# CAMERARX_CORE_0 register map
Vendor: Texas Instruments
Peripheral module from a debugger description file (folder am571x).
Registers are 32-bit, access not given, reset 0x427 unless marked. A register's access mark holds for its fields unless they carry their own. Offsets are as the file gives them; lines under a group give offsets from that group; [hi:lo] are bit positions; {n}, {i} and the like mark numbered series; 'fields as' and 'values as' point back to an identical list; <NAME> marks a mode.

## CAMERARX_CORE_0
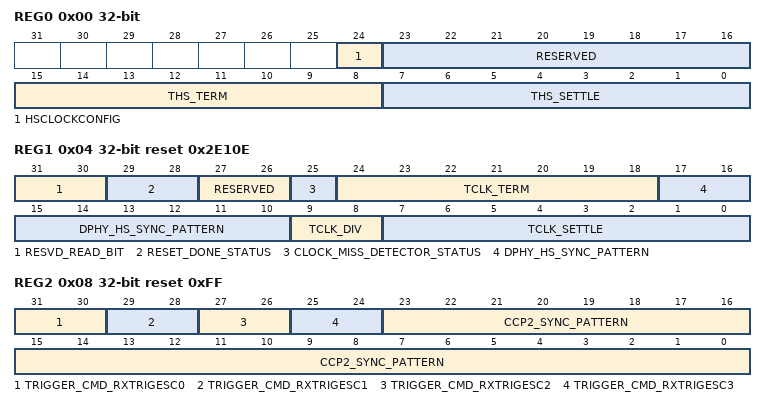
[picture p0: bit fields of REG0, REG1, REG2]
0x00 REG0 — First register. Note: For detailed description on parameter functionality, refer to MIPI D-PHY Specification v1.00.00.
  [24] HSCLOCKCONFIG rw — Disable clock missing detector
  [23:16] RESERVED ro — Read returns zero
  [15:8] THS_TERM rw — THS_TERM timing parameter in multiples of DDR clock frequency. Effective time for enabling of termination = synchronizer delay + timer delay + LPRX delay + combinational routing delay ~ (1–2)* DDRCLK + THS-TERM + ~ (1 –15) ns. Programmed value = floor(20 ns/DDR_CLK), where DDR_CLK is the period of the CSI-2 I/O lane rate. Default value: 4 (for 400 MHz).
  [7:0] THS_SETTLE rw — THS_SETTLE timing parameter in multiples of DDR clock frequency. Effective THS_SETTLE seen on line (starting to look for sync pattern) = synchronizer delay + timer delay + LPRX delay + combinational routing delay – pipeline delay in HS data path ~ (1–2)* DDRCLK + THS-SETTLE + ~ (1–15) ns –1*DDRCLK. Programmed value = floor(105 ns/DDR_CLK) + 4, where DDR_CLK is the period of the CSI-2 I/O lane rate. Default value: 39 (for 400 MHz). Minimum supported THS-SETTLE programmed value = 3.
0x04 REG1 reset 0x2E10E — Second register. Note: For detailed description on parameter functionality, refer to MIPI D-PHY Specification v1.00.00.
  [31:30] RESVD_READ_BIT — Reserved bit (access NA)
  [29:28] RESET_DONE_STATUS ro — Reset done read bits.
  [27:26] RESERVED rw — Write 0 for future compatibility.
  [25] CLOCK_MISS_DETECTOR_STATUS ro — Clock missing detector status. Internal debug bit. 1: Error in clock missing detector.
    0=CLKMISS_CAMSS_0 (Clock missing detector successful Note: CLKMISS detector is likely to malfunction, if tclk-trail section CAMSS Interrupt Events (60ns) is not honoured.)
  [24:18] TCLK_TERM rw — TCLK_TERM timing parameter in multiples of CTRLCLK Effective time for enabling of termination = synchronizer delay + timer delay + LPRX delay + combinational routing delay ~ (1–2)* CTRLCLK + TCLK_TERM + ~ (1–15) ns Programmed value = ceil(9.5 / CTRLCLK period) – 1 Default value : 0 (for 96 MHz)
  [17:10] DPHY_HS_SYNC_PATTERN rw — DPHY mode HS sync pattern in byte order (reverse of received order) See, CSI2 PHY Error Signals.
  [9:8] TCLK_DIV rw — CTRLCLK_DIV_FACTOR Divide factor for CTRLCLK for CLKMISS detector Programmed value = ceil (15ns/CTRLCLK Period) - 1 Default value: 1 (for 96 MHz) CLKMISS detection time = (5*TCLK_DIV+1)*(CTRLCLK period) &lt; 60ns Note: Only the CTRLCLK frequencies that satisfie above relationship are allowed. Typically, 96MHz will be used at CTRLCLK.
  [7:0] TCLK_SETTLE rw — TCLK_SETTLE timing parameter in multiples of CTRLCLK Clock Effective TCLK_SETTLE = synchronizer delay + timer delay + LPRX delay + combinational routing delay ~ (1–2)* CTRLCLK + Tclk-settle + ~ (1 –15) ns Programmed value = max[3, ceil(155 ns/CTRLCLK period) –1] Default value: 14 (for 96 MHz)
0x08 REG2 access per field reset 0xFF — Third register
  [31:30] TRIGGER_CMD_RXTRIGESC0 rw — Mapping of Trigger escape entry command to PPI output RXTRIGGERESC0 00 : '01100010' 01 : '01011101' 10: '00100001' 11: '10100000'
  [29:28] TRIGGER_CMD_RXTRIGESC1 rw — Mapping of Trigger escape entry command to PPI output RXTRIGGERESC1 00 : '01011101' 01 : '00100001' 10: '10100000' 11: '01100010'
  [27:26] TRIGGER_CMD_RXTRIGESC2 rw — Mapping of Trigger escape entry command to PPI output RXTRIGGERESC2 00 : '00100001' 01 : '01100010' 10: '01100010' 11: '01011101'
  [25:24] TRIGGER_CMD_RXTRIGESC3 rw — Mapping of Trigger escape entry command to PPI output RXTRIGGERESC3 00 : '10100000' 01 : '01100010' 10: '01011101' 11: '00100001'
  [23:0] CCP2_SYNC_PATTERN ro — CCP2 mode sync pattern in byte order (reverse of received order) See , CSI2 PHY Error Signals.
